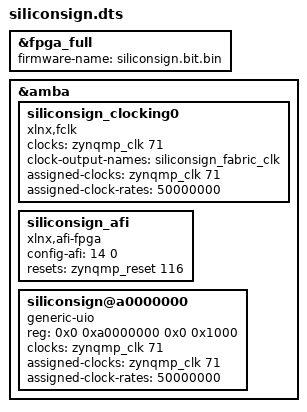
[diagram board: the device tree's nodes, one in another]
/dts-v1/;
/plugin/;
/ {
    fragment@0 {
        target = <&fpga_full>;
        __overlay__ {
            firmware-name = "siliconsign.bit.bin";
        };
    };
    fragment@1 {
        target = <&amba>;
        __overlay__ {
            #address-cells = <2>;
            #size-cells = <2>;
            siliconsign_clocking0 {
                compatible = "xlnx,fclk";
                status = "okay";
                #clock-cells = <0>;
                clocks = <&zynqmp_clk 71>;
                clock-output-names = "siliconsign_fabric_clk";
                assigned-clocks = <&zynqmp_clk 71>;
                assigned-clock-rates = <50000000>;
            };
            siliconsign_afi {
                compatible = "xlnx,afi-fpga";
                config-afi = <14 0>;
                resets = <&zynqmp_reset 116>;
                status = "okay";
            };
            siliconsign@a0000000 {
                compatible = "generic-uio";
                reg = <0x0 0xa0000000 0x0 0x1000>;
                clock-names = "s_axi_aclk";
                clocks = <&zynqmp_clk 71>;
                assigned-clocks = <&zynqmp_clk 71>;
                assigned-clock-rates = <50000000>;
                status = "okay";
            };
        };
    };
};
